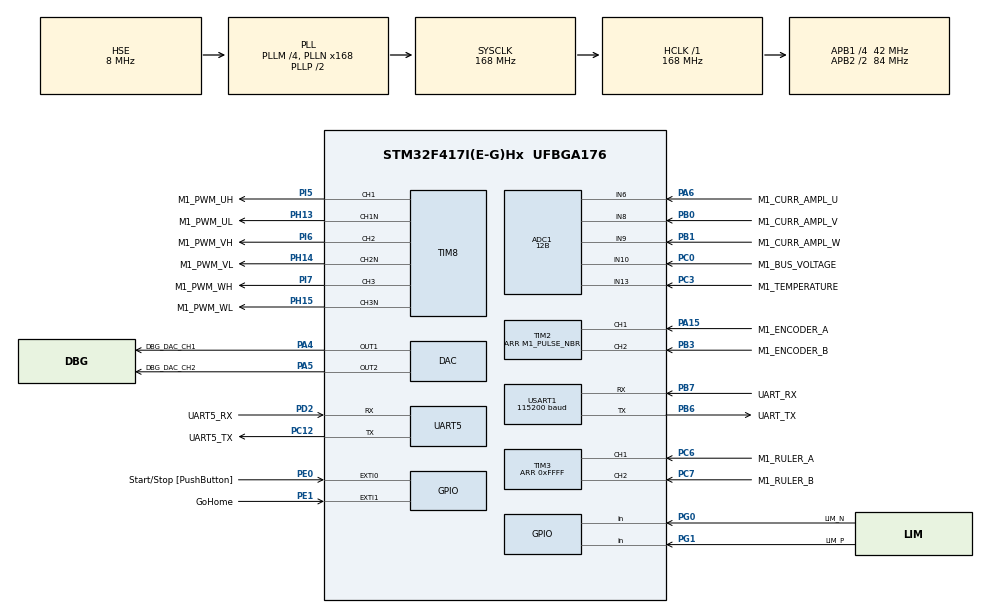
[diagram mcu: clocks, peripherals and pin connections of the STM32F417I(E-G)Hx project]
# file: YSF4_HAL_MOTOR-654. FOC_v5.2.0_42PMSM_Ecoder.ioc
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ADC1.Channel-1\#ChannelInjectedConversion=ADC_CHANNEL_6
ADC1.Channel-1\#ChannelRegularConversion=ADC_CHANNEL_10
ADC1.Channel-2\#ChannelInjectedConversion=ADC_CHANNEL_8
ADC1.Channel-2\#ChannelRegularConversion=ADC_CHANNEL_13
ADC1.Channel-3\#ChannelInjectedConversion=ADC_CHANNEL_9
ADC1.ClockPrescaler=ADC_CLOCK_SYNC_PCLK_DIV4
ADC1.ContinuousConvMode=DISABLE
ADC1.DMAContinuousRequests=DISABLE
ADC1.DataAlign=ADC_DATAALIGN_LEFT
ADC1.DiscontinuousConvMode=DISABLE
ADC1.EOCSelection=ADC_EOC_SINGLE_CONV
ADC1.EnableAnalogWatchDog=false
ADC1.EnableInjectedConversion=ENABLE
ADC1.EnableRegularConversion=ENABLE
ADC1.ExternalTrigConv=ADC_SOFTWARE_START
ADC1.ExternalTrigConvEdge=ADC_EXTERNALTRIGCONVEDGE_NONE
ADC1.ExternalTrigInjecConv=ADC_EXTERNALTRIGINJECCONV_T8_CC4
ADC1.ExternalTrigInjecConvEdge=ADC_EXTERNALTRIGINJECCONVEDGE_RISING
ADC1.InjNumberOfConversion=3
ADC1.InjectedConvMode=Discontinuous
ADC1.InjectedOffset-1\#ChannelInjectedConversion=0
ADC1.InjectedOffset-2\#ChannelInjectedConversion=0
ADC1.InjectedOffset-3\#ChannelInjectedConversion=0
ADC1.NbrOfConversion=2
ADC1.NbrOfConversionFlag=1
ADC1.Offset-1\#ChannelRegularConversion=0
ADC1.Offset-2\#ChannelRegularConversion=0
ADC1.OffsetNumber-1\#ChannelRegularConversion=ADC_OFFSET_NONE
ADC1.OffsetNumber-2\#ChannelRegularConversion=ADC_OFFSET_NONE
ADC1.Rank-1\#ChannelInjectedConversion=1
ADC1.Rank-1\#ChannelRegularConversion=1
ADC1.Rank-2\#ChannelInjectedConversion=2
ADC1.Rank-2\#ChannelRegularConversion=2
ADC1.Rank-3\#ChannelInjectedConversion=3
ADC1.Resolution=ADC_RESOLUTION_12B
ADC1.SamplingTime-1\#ChannelInjectedConversion=ADC_SAMPLETIME_3CYCLES
ADC1.SamplingTime-1\#ChannelRegularConversion=ADC_SAMPLETIME_56CYCLES
ADC1.SamplingTime-2\#ChannelInjectedConversion=ADC_SAMPLETIME_3CYCLES
ADC1.SamplingTime-2\#ChannelRegularConversion=ADC_SAMPLETIME_28CYCLES
ADC1.SamplingTime-3\#ChannelInjectedConversion=ADC_SAMPLETIME_3CYCLES
ADC1.ScanConvMode=ENABLE
ADC1.master=1
ADC2.Channel-1\#ChannelInjectedConversion=ADC_CHANNEL_6
ADC2.Channel-1\#ChannelRegularConversion=ADC_CHANNEL_6
ADC2.Channel-2\#ChannelInjectedConversion=ADC_CHANNEL_8
ADC2.Channel-3\#ChannelInjectedConversion=ADC_CHANNEL_9
ADC2.ClockPrescaler=ADC_CLOCK_SYNC_PCLK_DIV4
ADC2.ContinuousConvMode=DISABLE
ADC2.DMAContinuousRequests=DISABLE
ADC2.DataAlign=ADC_DATAALIGN_LEFT
ADC2.DiscontinuousConvMode=DISABLE
ADC2.EOCSelection=ADC_EOC_SINGLE_CONV
ADC2.EnableAnalogWatchDog=false
ADC2.EnableInjectedConversion=ENABLE
ADC2.EnableRegularConversion=ENABLE
ADC2.ExternalTrigConv=ADC_SOFTWARE_START
ADC2.ExternalTrigConvEdge=ADC_EXTERNALTRIGCONVEDGE_NONE
ADC2.ExternalTrigInjecConv=ADC_EXTERNALTRIGINJECCONV_T8_CC4
ADC2.ExternalTrigInjecConvEdge=ADC_EXTERNALTRIGINJECCONVEDGE_RISING
ADC2.InjNumberOfConversion=3
ADC2.InjectedConvMode=Discontinuous
ADC2.InjectedOffset-1\#ChannelInjectedConversion=0
ADC2.InjectedOffset-2\#ChannelInjectedConversion=0
ADC2.InjectedOffset-3\#ChannelInjectedConversion=0
ADC2.NbrOfConversion=1
ADC2.NbrOfConversionFlag=1
ADC2.Rank-1\#ChannelInjectedConversion=1
ADC2.Rank-1\#ChannelRegularConversion=1
ADC2.Rank-2\#ChannelInjectedConversion=2
ADC2.Rank-3\#ChannelInjectedConversion=3
ADC2.Resolution=ADC_RESOLUTION_12B
ADC2.SamplingTime-1\#ChannelInjectedConversion=ADC_SAMPLETIME_3CYCLES
ADC2.SamplingTime-1\#ChannelRegularConversion=ADC_SAMPLETIME_3CYCLES
ADC2.SamplingTime-2\#ChannelInjectedConversion=ADC_SAMPLETIME_3CYCLES
ADC2.SamplingTime-3\#ChannelInjectedConversion=ADC_SAMPLETIME_3CYCLES
ADC2.ScanConvMode=ENABLE
DAC.DAC_OutputBuffer=DAC_OUTPUTBUFFER_DISABLE
DAC.DAC_OutputBuffer2=DAC_OUTPUTBUFFER_DISABLE
DAC.DAC_Trigger=DAC_TRIGGER_SOFTWARE
DAC.DAC_Trigger2=DAC_TRIGGER_SOFTWARE
ExtraMW=MotorControl
ExtraMW.MotorControl.Config=MotorControl
ExtraMW.MotorControl.Mode=MotorControl
ExtraMW.MotorControl.Root=MCSDK_v5.2.0-Full/MotorControl
ExtraMW.MotorControl.Template=templates
Mcu.Family=STM32F4
Mcu.Name=STM32F417I(E-G)Hx
Mcu.Package=UFBGA176
MotorControl.ADC_1_PERIPH=ADC1
MotorControl.ADC_2_PERIPH=ADC2
MotorControl.ADC_AHBPERIPH=RCC_AHBPeriph_ADC12
MotorControl.ADC_CLOCK_WB_DIV=1
MotorControl.ADC_CLOCK_WB_FREQ=21
MotorControl.ADC_PERIPH=ADC1
MotorControl.ALIGNMENT_ANGLE_DEG=90
MotorControl.ALIGNMENT_DURATION=700
MotorControl.AMPLIFICATION_GAIN=4.02
MotorControl.ANGC={0,0,0,0,0,0,0,0}
MotorControl.BEMF_CONSISTENCY_GAIN=64
MotorControl.BEMF_CONSISTENCY_TOL=64
MotorControl.BKIN1_FILTER=0
MotorControl.BKIN2_FILTER=0
MotorControl.BKIN2_MODE=NONE
MotorControl.BKIN_MODE=NONE
MotorControl.BOARD=CUSTOM
MotorControl.BRKIN2_GPIO_AF=GPIO_AF_2
MotorControl.BRKIN_GPIO_AF=GPIO_AF_2
MotorControl.BUS_VOLTAGE_READING=true
MotorControl.CLOCK_FREQUENCY=CPU_CLK_168_MHZ
MotorControl.CLOCK_SOURCE=EXTERNAL
MotorControl.CONSTANT1_D=284329
MotorControl.CONSTANT1_Q=284329
MotorControl.CONSTANT2_QD=23067
MotorControl.CORD_BEMF_CONSISTENCY_GAIN=64
MotorControl.CORD_BEMF_CONSISTENCY_TOL=64
MotorControl.CORD_F1=16384
MotorControl.CORD_F2=2048
MotorControl.CORD_FIFO_DEPTH_01HZ=64
MotorControl.CORD_FIFO_DEPTH_DPP=64
MotorControl.CORD_GAIN1=-23771
MotorControl.CORD_GAIN2=23965
MotorControl.CORD_MAX_ACCEL_DPPP=60
MotorControl.CORD_MEAS_ERRORS_BEFORE_FAULTS=200
MotorControl.CORD_VARIANCE_THRESHOLD=4
MotorControl.CPU_CLK_168_MHZ=true
MotorControl.CTRBDID=4
MotorControl.CURRENT_READING_TOPOLOGY=THREE_SHUNT_INDEPENDENT_RESOURCES
MotorControl.CURR_SAMPLING_TIME=3
MotorControl.DAC_EMULATED=false
MotorControl.DAC_FUNCTIONALITY=true
MotorControl.DAC_TIMER_CH1_GPIO_PIN=LL_GPIO_PIN_4
MotorControl.DAC_TIMER_CH1_GPIO_PORT=GPIOA
MotorControl.DAC_TIMER_CH2_GPIO_PIN=LL_GPIO_PIN_5
MotorControl.DAC_TIMER_CH2_GPIO_PORT=GPIOA
MotorControl.DAC_TIMER_REMAPPING=NO_REMAP
MotorControl.DAC_TIMER_SELECTION=TIM3
MotorControl.DC_CURRENT_RS_MEAS=3.13
MotorControl.DEBUG_DAC_CH1=true
MotorControl.DEBUG_DAC_CH2=true
MotorControl.DEFAULT_CONTROL_MODE=STC_SPEED_MODE
MotorControl.DEFAULT_DAC_CHANNEL_1=MC_PROTOCOL_REG_I_A
MotorControl.DEFAULT_DAC_CHANNEL_2=MC_PROTOCOL_REG_I_B
MotorControl.DEFAULT_DAC_MOTOR=0
MotorControl.DEFAULT_FLUX_COMPONENT=0
MotorControl.DEFAULT_TARGET_SPEED_RPM=1000
MotorControl.DEFAULT_TORQUE_COMPONENT=0
MotorControl.DISSIPATIVE_BRAKE_POLARITY=DOUT_ACTIVE_HIGH
MotorControl.DRIVES_NUMBER_SELECTION=SINGLEDRIVE
MotorControl.EMERGENCY2_STOP_GPIO_PIN=LL_GPIO_PIN_4
MotorControl.EMERGENCY2_STOP_GPIO_PORT=GPIOI
MotorControl.EMERGENCY_STOP_GPIO_PIN=LL_GPIO_PIN_4
MotorControl.EMERGENCY_STOP_GPIO_PORT=GPIOI
MotorControl.ENABLE_SL_ALGO_FROM_PHASE=3
MotorControl.ENCODER=true
MotorControl.ENCODER_AVAILABLE=true
MotorControl.ENCODER_PPR=1000
MotorControl.ENC_AVERAGING_FIFO_DEPTH=16
MotorControl.ENC_A_GPIO_PIN=LL_GPIO_PIN_15
MotorControl.ENC_A_GPIO_PORT=GPIOA
MotorControl.ENC_B_GPIO_PIN=LL_GPIO_PIN_3
MotorControl.ENC_B_GPIO_PORT=GPIOB
MotorControl.ENC_ICx_FILTER=17
MotorControl.ENC_INVERT_SPEED=false
MotorControl.ENC_MEAS_ERRORS_BEFORE_FAULTS=200
MotorControl.ENC_TIMER_REMAPPING=NO_REMAP_TIM2
MotorControl.ENC_TIMER_SELECTION=ENC_TIM2
MotorControl.EXT_CLK_8_MHZ=true
MotorControl.EXT_CLOCK_FREQUENCY=EXT_CLK_8_MHZ
MotorControl.F1=16384
MotorControl.F2=2048
MotorControl.FEEDBACK_NET_FILTERING=false
MotorControl.FEED_FORWARD_CURRENT_REG_ENABLING=false
MotorControl.FINAL_I_ALIGNMENT=1596
MotorControl.FLUX_WEAKENING_ENABLING=false
MotorControl.FW_KIDIV=32768
MotorControl.FW_KI_GAIN=5000
MotorControl.FW_KPDIV=32768
MotorControl.FW_KP_GAIN=3000
MotorControl.FW_VOLTAGE_REF=985
MotorControl.GAIN1=-23771
MotorControl.GAIN2=23965
MotorControl.H1_GPIO_PIN=LL_GPIO_PIN_10
MotorControl.H1_GPIO_PORT=GPIOH
MotorControl.H2_GPIO_PIN=LL_GPIO_PIN_11
MotorControl.H2_GPIO_PORT=GPIOH
MotorControl.H3_GPIO_PIN=LL_GPIO_PIN_12
MotorControl.H3_GPIO_PORT=GPIOH
MotorControl.HALL_AVERAGING_FIFO_DEPTH=6
MotorControl.HALL_ICx_FILTER=218
MotorControl.HALL_MEAS_ERRORS_BEFORE_FAULTS=200
MotorControl.HALL_PHASE_SHIFT=120
MotorControl.HALL_SENSORS_AVAILABLE=true
MotorControl.HALL_SENSORS_PLACEMENT=DEGREES_120
MotorControl.HALL_TIMER_REMAPPING=NO_REMAP_TIM5
MotorControl.HALL_TIMER_SELECTION=HALL_TIM5
MotorControl.HFI_AMPLITUDE=25
MotorControl.HFI_DC_0_COEFF=0.00146
MotorControl.HFI_DC_1_COEFF=0.002921
MotorControl.HFI_DC_2_COEFF=0.00146
MotorControl.HFI_DC_3_COEFF=1.889033
MotorControl.HFI_DC_4_COEFF=-0.894874
MotorControl.HFI_DEBUG_MODE=false
MotorControl.HFI_FREQUENCY=400
MotorControl.HFI_HIFRAMPLSCAN=25
MotorControl.HFI_HP_ID_0_COEFF=0.925191
MotorControl.HFI_HP_ID_1_COEFF=-1.850383
MotorControl.HFI_HP_ID_2_COEFF=0.925191
MotorControl.HFI_HP_ID_3_COEFF=1.844778
MotorControl.HFI_HP_ID_4_COEFF=-0.855987
MotorControl.HFI_IDH_DELAY=32400
MotorControl.HFI_LOCKFREQ=41
MotorControl.HFI_LP_ID_0_COEFF=0.009086
MotorControl.HFI_LP_ID_1_COEFF=0.018172
MotorControl.HFI_LP_ID_2_COEFF=0.009086
MotorControl.HFI_LP_ID_3_COEFF=1.712838
MotorControl.HFI_LP_ID_4_COEFF=-0.749181
MotorControl.HFI_MAXANGLEDIFF=3640
MotorControl.HFI_MINIMUM_SPEED_RPM=402
MotorControl.HFI_NOTCH_IQD_0_COEFF=0.962363
MotorControl.HFI_NOTCH_IQD_1_COEFF=-1.90103
MotorControl.HFI_NOTCH_IQD_2_COEFF=0.962363
MotorControl.HFI_NOTCH_IQD_3_COEFF=1.90103
MotorControl.HFI_NOTCH_IQD_4_COEFF=-0.924727
MotorControl.HFI_NSDETPOINTSSKIP=10
MotorControl.HFI_NSMAXDETPOINTS=20
MotorControl.HFI_NS_MIN_SAT_DIFF=0
MotorControl.HFI_PID_KIDIV=32768
MotorControl.HFI_PID_KI_DEFAULT=400
MotorControl.HFI_PID_KPDIV=16384
MotorControl.HFI_PID_KP_DEFAULT=800
MotorControl.HFI_PLL_KI_DEFAULT=0.00400
MotorControl.HFI_PLL_KP_DEFAULT=0.00060
MotorControl.HFI_RESTARTTIMESEC=0.1
MotorControl.HFI_RESTART_RPM_TH=(((HFI_STO_RPM_TH)+(STO_HFI_RPM_TH))/2)
MotorControl.HFI_REVERT_DIRECTION=true
MotorControl.HFI_SCANROTATIONSNO=3
MotorControl.HFI_SPD_BUFFER_DEPTH_01HZ=64
MotorControl.HFI_STEPANGLE=3640
MotorControl.HFI_STO_RPM_TH=OBS_MINIMUM_SPEED_RPM
MotorControl.HFI_WAITAFTERNS2=4
MotorControl.HFI_WAITBEFORESN=6
MotorControl.HFI_WAITSYNCH=20
MotorControl.HFI_WAITTRACK=20
MotorControl.HIGH_SIDE_BRAKE_STATE=false
MotorControl.HIGH_SIDE_IDLE_STATE=false
MotorControl.HW_COMPLEMENTED_LOW_SIDE=false
MotorControl.HW_DEAD_TIME_NS=100
MotorControl.HW_OV_CURRENT_PROT_BYPASS=false
MotorControl.ID_DEMAG=-4997
MotorControl.INRUSH_CURRLIMIT_AT_POWER_ON=true
MotorControl.INRUSH_CURRLIMIT_CHANGE_AFTER_MS=1000
MotorControl.INRUSH_CURRLIMIT_ENABLING=false
MotorControl.INRUSH_CURRLIMIT_GPIO_PIN=LL_GPIO_PIN_8
MotorControl.INRUSH_CURRLIMIT_GPIO_PORT=GPIOH
MotorControl.INRUSH_CURR_LIMITER_POLARITY=DOUT_ACTIVE_HIGH
MotorControl.INTERNAL_OVERCURRENTPROTECTION=false
MotorControl.INTERNAL_OVERVOLTAGEPROTECTION=false
MotorControl.IQMAX=4997
MotorControl.LCD_JOYSTICK_FUNCTIONALITY=false
MotorControl.LCD_MODE=LCD_FULL
MotorControl.LDLQ_RATIO=1.000
MotorControl.LOW_SIDE_BRAKE_STATE=false
MotorControl.LOW_SIDE_IDLE_STATE=false
MotorControl.LOW_SIDE_SIGNALS_ENABLING=LS_PWM_TIMER
MotorControl.LS=0.000620
MotorControl.MAX_APPLICATION_SPEED=3000
MotorControl.MAX_MODULATION_99_PER_CENT=true
MotorControl.MAX_MODULATION_INDEX=MAX_MODULATION_99_PER_CENT
MotorControl.MCU=STM32F417IG
MotorControl.MCU_SUPPLY_VOLTAGE=3.30
MotorControl.MCU_TYPE=STM32F4xx
MotorControl.MC_WORKBENCH_VERSION=5.2.0.18503
MotorControl.MEAS_ERRORS_BEFORE_FAULTS=200
MotorControl.MIN_APPLICATION_SPEED=0
MotorControl.MOTOR_MAX_SPEED_RPM=3000
MotorControl.MOTOR_TYPE=PMSM
MotorControl.MOTOR_VOLTAGE_CONSTANT=4.1
MotorControl.MTPA_ENABLING=false
MotorControl.NB_CONSECUTIVE_TESTS=2
MotorControl.NOMINAL_BUS_VOLTAGE_V=24
MotorControl.NOMINAL_CURRENT=4997
MotorControl.OBS_MEAS_ERRORS_BEFORE_FAULTS=200
MotorControl.OBS_MINIMUM_SPEED_RPM=580
MotorControl.OCPA_INVERTINGINPUT=COMPX_InvertingInput_VREF
MotorControl.OCPA_INVERTINGINPUT_GPIO_PIN=LL_GPIO_PIN_4
MotorControl.OCPA_INVERTINGINPUT_GPIO_PORT=GPIOA
MotorControl.OCPA_INVERTINGINPUT_MODE=INT_MODE
MotorControl.OCPA_NONINVERTINGINPUT=COMP1_NonInvertingInput_PA1
MotorControl.OCPA_NONINVERTINGINPUT_GPIO_PIN=LL_GPIO_PIN_1
MotorControl.OCPA_NONINVERTINGINPUT_GPIO_PORT=GPIOA
MotorControl.OCPA_OUTPUT=COMP_Output_TIM8BKIN2
MotorControl.OCPA_OUTPUTPOL=COMP_OutputPol_NonInverted
MotorControl.OCPA_OUTPUT_GPIO_AF=GPIO_AF_8
MotorControl.OCPA_OUTPUT_GPIO_PIN=LL_GPIO_PIN_0
MotorControl.OCPA_OUTPUT_GPIO_PORT=GPIOA
MotorControl.OCPA_OUTPUT_MODE=INT_MODE
MotorControl.OCPA_SELECTION=COMP1
MotorControl.OCPB_INVERTINGINPUT=COMPX_InvertingInput_VREF
MotorControl.OCPB_INVERTINGINPUT_GPIO_PIN=LL_GPIO_PIN_4
MotorControl.OCPB_INVERTINGINPUT_GPIO_PORT=GPIOA
MotorControl.OCPB_INVERTINGINPUT_MODE=INT_MODE
MotorControl.OCPB_NONINVERTINGINPUT=COMP2_NonInvertingInput_PA7
MotorControl.OCPB_NONINVERTINGINPUT_GPIO_PIN=LL_GPIO_PIN_7
MotorControl.OCPB_NONINVERTINGINPUT_GPIO_PORT=GPIOA
MotorControl.OCPB_OUTPUT=COMP_Output_TIM8BKIN2
MotorControl.OCPB_OUTPUTPOL=COMP_OutputPol_NonInverted
MotorControl.OCPB_OUTPUT_GPIO_AF=GPIO_AF_8
MotorControl.OCPB_OUTPUT_GPIO_PIN=LL_GPIO_PIN_2
MotorControl.OCPB_OUTPUT_GPIO_PORT=GPIOA
MotorControl.OCPB_OUTPUT_MODE=INT_MODE
MotorControl.OCPB_SELECTION=COMP2
MotorControl.OCPC_INVERTINGINPUT=COMPX_InvertingInput_VREF
MotorControl.OCPC_INVERTINGINPUT_GPIO_PIN=LL_GPIO_PIN_4
MotorControl.OCPC_INVERTINGINPUT_GPIO_PORT=GPIOA
MotorControl.OCPC_INVERTINGINPUT_MODE=INT_MODE
MotorControl.OCPC_NONINVERTINGINPUT=COMP3_NonInvertingInput_PD14
MotorControl.OCPC_NONINVERTINGINPUT_GPIO_PIN=LL_GPIO_PIN_14
MotorControl.OCPC_NONINVERTINGINPUT_GPIO_PORT=GPIOD
MotorControl.OCPC_OUTPUT=COMP_Output_TIM8BKIN2
MotorControl.OCPC_OUTPUTPOL=COMP_OutputPol_NonInverted
MotorControl.OCPC_OUTPUT_GPIO_AF=GPIO_AF_7
MotorControl.OCPC_OUTPUT_GPIO_PIN=LL_GPIO_PIN_8
MotorControl.OCPC_OUTPUT_GPIO_PORT=GPIOC
MotorControl.OCPC_OUTPUT_MODE=INT_MODE
MotorControl.OCPC_SELECTION=COMP3
MotorControl.OCPREF=23830
MotorControl.OCP_COMP_THRESHOLD=0.50
MotorControl.OCP_FILTER=COMP_Mode_HighSpeed
MotorControl.OCP_INVERTINGINPUT=COMPX_InvertingInput_VREF
MotorControl.OCP_INVERTINGINPUT_GPIO_PIN=LL_GPIO_PIN_4
MotorControl.OCP_INVERTINGINPUT_GPIO_PORT=GPIOA
MotorControl.OCP_INVERTINGINPUT_MODE=INT_MODE
MotorControl.OCP_NONINVERTINGINPUT=COMP2_NonInvertingInput_PA7
MotorControl.OCP_NONINVERTINGINPUT_GPIO_PIN=LL_GPIO_PIN_7
MotorControl.OCP_NONINVERTINGINPUT_GPIO_PORT=GPIOA
MotorControl.OCP_OUTPUT=COMP_Output_TIM8BKIN2
MotorControl.OCP_OUTPUTPOL=COMP_OutputPol_NonInverted
MotorControl.OCP_OUTPUT_GPIO_AF=GPIO_AF_8
MotorControl.OCP_OUTPUT_GPIO_PIN=LL_GPIO_PIN_2
MotorControl.OCP_OUTPUT_GPIO_PORT=GPIOA
MotorControl.OCP_OUTPUT_MODE=INT_MODE
MotorControl.OCP_SELECTION=COMP2
MotorControl.OFST={0,0,0,0,0,0,0,0}
MotorControl.ON_OVER_VOLTAGE=TURN_OFF_PWM
MotorControl.OPAMP1_INVERTINGINPUT=OPAMP1_InvertingInput_PGA
MotorControl.OPAMP1_INVERTINGINPUT_GPIO_PIN=LL_GPIO_PIN_3
MotorControl.OPAMP1_INVERTINGINPUT_GPIO_PORT=GPIOA
MotorControl.OPAMP1_INVERTINGINPUT_MODE=INT_MODE
MotorControl.OPAMP1_NONINVERTINGINPUT_PHA=OPAMP1_NonInvertingInput_PA1
MotorControl.OPAMP1_NONINVERTINGINPUT_PHA_GPIO_PIN=LL_GPIO_PIN_1
MotorControl.OPAMP1_NONINVERTINGINPUT_PHA_GPIO_PORT=GPIOA
MotorControl.OPAMP1_NONINVERTINGINPUT_PHB=OPAMP1_NonInvertingInput_PA7
MotorControl.OPAMP1_NONINVERTINGINPUT_PHB_GPIO_PIN=LL_GPIO_PIN_7
MotorControl.OPAMP1_NONINVERTINGINPUT_PHB_GPIO_PORT=GPIOA
MotorControl.OPAMP1_OUT_GPIO_PIN=LL_GPIO_PIN_2
MotorControl.OPAMP1_OUT_GPIO_PORT=GPIOA
MotorControl.OPAMP1_SELECTION=OPAMP1
MotorControl.OPAMP2_INVERTINGINPUT=OPAMP2_InvertingInput_PGA
MotorControl.OPAMP2_INVERTINGINPUT_GPIO_PIN=LL_GPIO_PIN_5
MotorControl.OPAMP2_INVERTINGINPUT_GPIO_PORT=GPIOC
MotorControl.OPAMP2_INVERTINGINPUT_MODE=INT_MODE
MotorControl.OPAMP2_NONINVERTINGINPUT_PHA=OPAMP2_NonInvertingInput_PD14
MotorControl.OPAMP2_NONINVERTINGINPUT_PHA_GPIO_PIN=LL_GPIO_PIN_14
MotorControl.OPAMP2_NONINVERTINGINPUT_PHA_GPIO_PORT=GPIOD
MotorControl.OPAMP2_NONINVERTINGINPUT_PHB=OPAMP2_NonInvertingInput_PA7
MotorControl.OPAMP2_NONINVERTINGINPUT_PHB_GPIO_PIN=LL_GPIO_PIN_7
MotorControl.OPAMP2_NONINVERTINGINPUT_PHB_GPIO_PORT=GPIOA
MotorControl.OPAMP2_NONINVERTINGINPUT_PHC=OPAMP2_NonInvertingInput_PD14
MotorControl.OPAMP2_NONINVERTINGINPUT_PHC_GPIO_PIN=LL_GPIO_PIN_14
MotorControl.OPAMP2_NONINVERTINGINPUT_PHC_GPIO_PORT=GPIOD
MotorControl.OPAMP2_OUT_GPIO_PIN=LL_GPIO_PIN_6
MotorControl.OPAMP2_OUT_GPIO_PORT=GPIOA
MotorControl.OPAMP2_SELECTION=OPAMP2
MotorControl.OPAMP_INVERTINGINPUT=OPAMP1_InvertingInput_PGA
MotorControl.OPAMP_INVERTINGINPUT_GPIO_PIN=LL_GPIO_PIN_3
MotorControl.OPAMP_INVERTINGINPUT_GPIO_PORT=GPIOA
MotorControl.OPAMP_INVERTINGINPUT_MODE=INT_MODE
MotorControl.OPAMP_NONINVERTINGINPUT=OPAMP1_NonInvertingInput_PA7
MotorControl.OPAMP_NONINVERTINGINPUT_GPIO_PIN=LL_GPIO_PIN_7
MotorControl.OPAMP_NONINVERTINGINPUT_GPIO_PORT=GPIOA
MotorControl.OPAMP_OUT_GPIO_PIN=LL_GPIO_PIN_2
MotorControl.OPAMP_OUT_GPIO_PORT=GPIOA
MotorControl.OPAMP_PGACONNECT=OPAMP_PGAConnect_No
MotorControl.OPAMP_PGAGAIN=OPAMP_OPAMP_PGAGain_2
MotorControl.OPAMP_SELECTION=OPAMP1
MotorControl.OPAMP_TYPE_GAIN=INTERNAL
MotorControl.OPEN_LOOP_FOC=false
MotorControl.OPEN_LOOP_K=44
MotorControl.OPEN_LOOP_OFF=4400
MotorControl.OPEN_LOOP_SPEED_RAMP_DURATION_MS=1000
MotorControl.OPEN_LOOP_SPEED_RPM=100
MotorControl.OPEN_LOOP_VF=false
MotorControl.OPEN_LOOP_VOLTAGE_d=6000
MotorControl.OVERCURR_FEEDBACK_POLARITY=EMSTOP_ACTIVE_LOW
MotorControl.OVERCURR_PROTECTION_HW_DISABLING=DOUT_ACTIVE_HIGH
MotorControl.OVPREF=23830
MotorControl.OVP_FILTER=COMP_Mode_HighSpeed
MotorControl.OVP_INVERTINGINPUT=COMPX_InvertingInput_VREF
MotorControl.OVP_INVERTINGINPUT_GPIO_PIN=LL_GPIO_PIN_4
MotorControl.OVP_INVERTINGINPUT_GPIO_PORT=GPIOA
MotorControl.OVP_INVERTINGINPUT_MODE=INT_MODE
MotorControl.OVP_NONINVERTINGINPUT=COMP7_NonInvertingInput_PA0
MotorControl.OVP_NONINVERTINGINPUT_GPIO_PIN=LL_GPIO_PIN_0
MotorControl.OVP_NONINVERTINGINPUT_GPIO_PORT=GPIOA
MotorControl.OVP_OUTPUT=COMP_Output_TIM8BKIN
MotorControl.OVP_OUTPUTPOL=COMP_OutputPol_NonInverted
MotorControl.OVP_OUTPUT_GPIO_AF=GPIO_AF_3
MotorControl.OVP_OUTPUT_GPIO_PIN=LL_GPIO_PIN_2
MotorControl.OVP_OUTPUT_GPIO_PORT=GPIOC
MotorControl.OVP_OUTPUT_MODE=INT_MODE
MotorControl.OVP_SELECTION=COMP7
MotorControl.OV_CURR_BYPASS_GPIO_PIN=LL_GPIO_PIN_8
MotorControl.OV_CURR_BYPASS_GPIO_PORT=GPIOC
MotorControl.OV_TEMPERATURE_HYSTERESIS_C=10
MotorControl.OV_TEMPERATURE_PROT_ENABLING=true
MotorControl.OV_TEMPERATURE_THRESHOLD_C=70
MotorControl.OV_VOLTAGE_PROT_ENABLING=true
MotorControl.OV_VOLTAGE_THRESHOLD_V=60
MotorControl.PHASE1_DURATION=0
MotorControl.PHASE1_FINAL_CURRENT=0
MotorControl.PHASE1_FINAL_SPEED_RPM=0
MotorControl.PHASE2_DURATION=700
MotorControl.PHASE2_FINAL_CURRENT=957
MotorControl.PHASE2_FINAL_SPEED_RPM=0
MotorControl.PHASE3_DURATION=350
MotorControl.PHASE3_FINAL_CURRENT=1117
MotorControl.PHASE3_FINAL_SPEED_RPM=630
MotorControl.PHASE4_DURATION=1150
MotorControl.PHASE4_FINAL_CURRENT=1117
MotorControl.PHASE4_FINAL_SPEED_RPM=2700
MotorControl.PHASE5_DURATION=0
MotorControl.PHASE5_FINAL_CURRENT=1117
MotorControl.PHASE5_FINAL_SPEED_RPM=2700
MotorControl.PHASE_CURRENTS_ADC=ADC123
MotorControl.PHASE_CURRENTS_CHANNEL=ADC_CHANNEL_11
MotorControl.PHASE_CURRENTS_GPIO_PIN=LL_GPIO_PIN_1
MotorControl.PHASE_CURRENTS_GPIO_PORT=GPIOC
MotorControl.PHASE_UH_GPIO_AF=GPIO_AF_2
MotorControl.PHASE_UH_GPIO_PIN=LL_GPIO_PIN_5
MotorControl.PHASE_UH_GPIO_PORT=GPIOI
MotorControl.PHASE_UH_POLARITY=H_ACTIVE_HIGH
MotorControl.PHASE_UL_GPIO_AF=GPIO_AF_2
MotorControl.PHASE_UL_GPIO_PIN=LL_GPIO_PIN_13
MotorControl.PHASE_UL_GPIO_PORT=GPIOH
MotorControl.PHASE_UL_POLARITY=L_ACTIVE_HIGH
MotorControl.PHASE_U_CURR_ADC=ADC1_2
MotorControl.PHASE_U_CURR_CHANNEL=ADC_CHANNEL_6
MotorControl.PHASE_U_GPIO_PIN=LL_GPIO_PIN_6
MotorControl.PHASE_U_GPIO_PORT=GPIOA
MotorControl.PHASE_VH_GPIO_AF=GPIO_AF_2
MotorControl.PHASE_VH_GPIO_PIN=LL_GPIO_PIN_6
MotorControl.PHASE_VH_GPIO_PORT=GPIOI
MotorControl.PHASE_VH_POLARITY=H_ACTIVE_HIGH
MotorControl.PHASE_VL_GPIO_AF=GPIO_AF_2
MotorControl.PHASE_VL_GPIO_PIN=LL_GPIO_PIN_14
MotorControl.PHASE_VL_GPIO_PORT=GPIOH
MotorControl.PHASE_VL_POLARITY=L_ACTIVE_HIGH
MotorControl.PHASE_V_CURR_ADC=ADC1_2
MotorControl.PHASE_V_CURR_CHANNEL=ADC_CHANNEL_8
MotorControl.PHASE_V_GPIO_PIN=LL_GPIO_PIN_0
MotorControl.PHASE_V_GPIO_PORT=GPIOB
MotorControl.PHASE_WH_GPIO_AF=GPIO_AF_2
MotorControl.PHASE_WH_GPIO_PIN=LL_GPIO_PIN_7
MotorControl.PHASE_WH_GPIO_PORT=GPIOI
MotorControl.PHASE_WH_POLARITY=H_ACTIVE_HIGH
MotorControl.PHASE_WL_GPIO_AF=GPIO_AF_2
MotorControl.PHASE_WL_GPIO_PIN=LL_GPIO_PIN_15
MotorControl.PHASE_WL_GPIO_PORT=GPIOH
MotorControl.PHASE_WL_POLARITY=L_ACTIVE_HIGH
MotorControl.PHASE_W_CURR_ADC=ADC1_2
MotorControl.PHASE_W_CURR_CHANNEL=ADC_CHANNEL_9
MotorControl.PHASE_W_GPIO_PIN=LL_GPIO_PIN_1
MotorControl.PHASE_W_GPIO_PORT=GPIOB
MotorControl.PID_FLUX_KD_DEFAULT=100
MotorControl.PID_FLUX_KI_DEFAULT=2277
MotorControl.PID_FLUX_KP_DEFAULT=2172
MotorControl.PID_SPEED_KD_DEFAULT=0
MotorControl.PID_SPEED_KI_DEFAULT=50
MotorControl.PID_SPEED_KP_DEFAULT=100
MotorControl.PID_TORQUE_KD_DEFAULT=100
MotorControl.PID_TORQUE_KI_DEFAULT=2277
MotorControl.PID_TORQUE_KP_DEFAULT=2172
MotorControl.PLL_KI_GAIN=17
MotorControl.PLL_KP_GAIN=399
MotorControl.POLE_PAIR_NUM=4
MotorControl.PWBDID=0
MotorControl.PWM_FREQUENCY=16000
MotorControl.PWM_TIMER_REMAPPING=PWM_NO_REMAP
MotorControl.PWM_TIMER_SELECTION=PWM_TIM8
MotorControl.REGCONVADC=ADC1
MotorControl.REGULATION_EXECUTION_RATE=1
MotorControl.RS=0.65
MotorControl.RSHUNT=0.020
MotorControl.R_BRAKE_GPIO_PIN=LL_GPIO_PIN_8
MotorControl.R_BRAKE_GPIO_PORT=GPIOC
MotorControl.R_BRAKE_SWITCH_OFF_THRES_V=48
MotorControl.SEGDIV=0
MotorControl.SERIAL_COMMUNICATION=true
MotorControl.SERIAL_COM_CHANNEL1=MC_PROTOCOL_REG_I_A
MotorControl.SERIAL_COM_CHANNEL2=MC_PROTOCOL_REG_I_A
MotorControl.SERIAL_COM_MODE=COM_BIDIRECTIONAL
MotorControl.SERIAL_COM_MOTOR=0
MotorControl.SHARED_SIGNAL_ENABLE=false
MotorControl.SINGLEDRIVE=true
MotorControl.SPD_DIFFERENTIAL_TERM_ENABLING=false
MotorControl.SPEED_BAND_LOWER_LIMIT=15
MotorControl.SPEED_BAND_UPPER_LIMIT=17
MotorControl.SPEED_LOOP_FREQUENCY_HZ=500
MotorControl.SPEED_SENSOR_SELECTION=ENCODER
MotorControl.SP_KDDIV=16
MotorControl.SP_KIDIV=256
MotorControl.SP_KPDIV=16
MotorControl.STARTING_ANGLE_DEG=90
MotorControl.START_STOP_BTN=true
MotorControl.START_STOP_GPIO_PIN=LL_GPIO_PIN_0
MotorControl.START_STOP_GPIO_PORT=GPIOE
MotorControl.START_STOP_POLARITY=DIN_ACTIVE_LOW
MotorControl.STM32F4xx=true
MotorControl.STO_FIFO_DEPTH_01HZ=64
MotorControl.STO_FIFO_DEPTH_DPP=64
MotorControl.STO_HFI_RPM_TH=460
MotorControl.SW_DEADTIME_NS=200
MotorControl.SW_OV_CURRENT_PROT_ENABLING=false
MotorControl.T0_C=25
MotorControl.TEMPERATURE_READING=true
MotorControl.TEMP_ADC_SAMPLING_TIME=28
MotorControl.TEMP_FDBK_ADC=ADC123
MotorControl.TEMP_FDBK_CHANNEL=ADC_CHANNEL_13
MotorControl.TEMP_FDBK_GPIO_PIN=LL_GPIO_PIN_3
MotorControl.TEMP_FDBK_GPIO_PORT=GPIOC
MotorControl.TFDIFFERENTIAL_TERM_ENABLING=false
MotorControl.TF_KDDIV=8192
MotorControl.TF_KIDIV=16384
MotorControl.TF_KPDIV=1024
MotorControl.THREE_SHUNT_INDEPENDENT_RESOURCES=true
MotorControl.TNOISE_NS=2550
MotorControl.TRANSITION_DURATION=25
MotorControl.TRISE_NS=2550
MotorControl.T_MAX=70
MotorControl.UD_VOLTAGE_THRESHOLD_V=12
MotorControl.USART_REMAPPING=NO_REMAP_USART1
MotorControl.USART_RX_GPIO_PIN=LL_GPIO_PIN_7
MotorControl.USART_RX_GPIO_PORT=GPIOB
MotorControl.USART_SELECTION=USE_USART1
MotorControl.USART_SPEED=115200
MotorControl.USART_TX_GPIO_PIN=LL_GPIO_PIN_6
MotorControl.USART_TX_GPIO_PORT=GPIOB
MotorControl.USE_INTERNAL_OPAMP=false
MotorControl.UV_VOLTAGE_PROT_ENABLING=true
MotorControl.V0_V=0.926
MotorControl.VARIANCE_THRESHOLD=0.1
MotorControl.VBUS_ADC=ADC123
MotorControl.VBUS_ADC_SAMPLING_TIME=56
MotorControl.VBUS_CHANNEL=ADC_CHANNEL_10
MotorControl.VBUS_GPIO_PIN=LL_GPIO_PIN_0
MotorControl.VBUS_GPIO_PORT=GPIOC
MotorControl.VBUS_PARTITIONING_FACTOR=0.0463
MotorControl.WB_to_Mx_template_version=18-08-02
MotorControl.WB_to_Mx_version=0.13.3
MotorControl.dV_dT=0.030
NVIC.ADC_IRQn=true\:2\:0\:true\:true\:false\:1\:false\:true\:true
NVIC.EXTI0_IRQn=true\:0\:0\:false\:true\:false\:6\:true\:true\:true
NVIC.EXTI1_IRQn=true\:0\:0\:false\:false\:true\:true\:true\:true
NVIC.PriorityGroup=NVIC_PRIORITYGROUP_3
NVIC.TIM2_IRQn=true\:3\:0\:false\:true\:false\:4\:true\:true\:true
NVIC.TIM3_IRQn=true\:0\:0\:false\:false\:true\:true\:true\:true
NVIC.TIM8_BRK_TIM12_IRQn=true\:4\:1\:false\:true\:false\:3\:true\:true\:true
NVIC.TIM8_UP_TIM13_IRQn=true\:0\:0\:false\:true\:false\:2\:true\:true\:true
NVIC.UART5_IRQn=true\:0\:0\:false\:false\:true\:true\:true\:true
NVIC.USART1_IRQn=true\:3\:1\:true\:true\:false\:5\:true\:true\:true
PA15.GPIO_Label=M1_ENCODER_A
PA15.Signal=S_TIM2_CH1_ETR
PA4.GPIO_Label=DBG_DAC_CH1
PA4.Signal=COMP_DAC1_group
PA5.GPIO_Label=DBG_DAC_CH2
PA5.Signal=COMP_DAC2_group
PA6.GPIO_Label=M1_CURR_AMPL_U
PA6.Signal=SharedAnalog_PA6
PB0.GPIO_Label=M1_CURR_AMPL_V
PB0.Signal=SharedAnalog_PB0
PB1.GPIO_Label=M1_CURR_AMPL_W
PB1.Signal=SharedAnalog_PB1
PB3.GPIO_Label=M1_ENCODER_B
PB3.Signal=S_TIM2_CH2
PB6.GPIO_Label=UART_TX
PB6.GPIO_Mode=GPIO_MODE_AF_PP
PB6.GPIO_PuPd=GPIO_NOPULL
PB6.GPIO_Speed=GPIO_SPEED_FREQ_LOW
PB6.Mode=Asynchronous
PB6.Signal=USART1_TX
PB7.GPIO_Label=UART_RX
PB7.GPIO_Mode=GPIO_MODE_AF_PP
PB7.GPIO_PuPd=GPIO_NOPULL
PB7.GPIO_Speed=GPIO_SPEED_FREQ_LOW
PB7.Mode=Asynchronous
PB7.Signal=USART1_RX
PC0.GPIO_Label=M1_BUS_VOLTAGE
PC0.Signal=ADCx_IN10
PC12.GPIO_Label=UART5_TX
PC12.GPIO_Speed=GPIO_SPEED_FREQ_LOW
PC12.Mode=Asynchronous
PC12.Signal=UART5_TX
PC3.GPIO_Label=M1_TEMPERATURE
PC3.Signal=ADCx_IN13
PC6.GPIO_Label=M1_RULER_A
PC6.Signal=S_TIM3_CH1
PC7.GPIO_Label=M1_RULER_B
PC7.Signal=S_TIM3_CH2
PD2.GPIO_Label=UART5_RX
PD2.GPIO_Speed=GPIO_SPEED_FREQ_LOW
PD2.Mode=Asynchronous
PD2.Signal=UART5_RX
PE0.GPIO_Label=Start/Stop [PushButton]
PE0.GPIO_ModeDefaultEXTI=GPIO_MODE_IT_FALLING
PE0.Signal=GPXTI0
PE1.GPIO_Label=GoHome
PE1.Signal=GPXTI1
PG0.GPIO_Label=LIM_N
PG0.Signal=GPIO_Input
PG1.GPIO_Label=LIM_P
PG1.Signal=GPIO_Input
PH0-OSC_IN.Mode=HSE-External-Oscillator
PH0-OSC_IN.Signal=RCC_OSC_IN
PH1-OSC_OUT.Mode=HSE-External-Oscillator
PH1-OSC_OUT.Signal=RCC_OSC_OUT
PH13.GPIO_Label=M1_PWM_UL
PH13.GPIO_PuPd=GPIO_PULLDOWN
PH13.GPIO_Speed=GPIO_SPEED_FREQ_HIGH
PH13.Mode=PWM Generation1 CH1 CH1N
PH13.Signal=TIM8_CH1N
PH14.GPIO_Label=M1_PWM_VL
PH14.GPIO_PuPd=GPIO_PULLDOWN
PH14.GPIO_Speed=GPIO_SPEED_FREQ_HIGH
PH14.Mode=PWM Generation2 CH2 CH2N
PH14.Signal=TIM8_CH2N
PH15.GPIO_Label=M1_PWM_WL
PH15.GPIO_PuPd=GPIO_PULLDOWN
PH15.GPIO_Speed=GPIO_SPEED_FREQ_HIGH
PH15.Mode=PWM Generation3 CH3 CH3N
PH15.Signal=TIM8_CH3N
PI5.GPIO_Label=M1_PWM_UH
PI5.GPIO_PuPd=GPIO_PULLDOWN
PI5.GPIO_Speed=GPIO_SPEED_FREQ_HIGH
PI5.Signal=S_TIM8_CH1
PI6.GPIO_Label=M1_PWM_VH
PI6.GPIO_PuPd=GPIO_PULLDOWN
PI6.GPIO_Speed=GPIO_SPEED_FREQ_HIGH
PI6.Signal=S_TIM8_CH2
PI7.GPIO_Label=M1_PWM_WH
PI7.GPIO_PuPd=GPIO_PULLDOWN
PI7.GPIO_Speed=GPIO_SPEED_FREQ_HIGH
PI7.Signal=S_TIM8_CH3
ProjectManager.HeapSize=0x200
ProjectManager.StackSize=0x400
ProjectManager.TargetToolchain=MDK-ARM V5
RCC.48MHZClocksFreq_Value=84000000
RCC.AHBFreq_Value=168000000
RCC.APB1CLKDivider=RCC_HCLK_DIV4
RCC.APB1Freq_Value=42000000
RCC.APB1TimFreq_Value=84000000
RCC.APB2CLKDivider=RCC_HCLK_DIV2
RCC.APB2Freq_Value=84000000
RCC.APB2TimFreq_Value=168000000
RCC.CortexFreq_Value=168000000
RCC.EnbaleCSS=true
RCC.HCLKFreq_Value=168000000
RCC.HSE_VALUE=8000000
RCC.HSI_VALUE=16000000
RCC.LSE_VALUE=32768
RCC.PLLM=4
RCC.PLLN=168
RCC.PLLSourceVirtual=RCC_PLLSOURCE_HSE
RCC.SYSCLKFreq_VALUE=168000000
RCC.SYSCLKSource=RCC_SYSCLKSOURCE_PLLCLK
RCC.VCOOutputFreq_Value=336000000
SH.ADCx_IN10.0=ADC1_IN10,IN10
SH.ADCx_IN13.0=ADC1_IN13,IN13
SH.COMP_DAC1_group.0=DAC_OUT1,DAC_OUT1
SH.COMP_DAC2_group.0=DAC_OUT2,DAC_OUT2
SH.S_TIM2_CH1_ETR.0=TIM2_CH1,Encoder_Interface
SH.S_TIM2_CH2.0=TIM2_CH2,Encoder_Interface
SH.S_TIM3_CH1.0=TIM3_CH1,Encoder_Interface
SH.S_TIM3_CH2.0=TIM3_CH2,Encoder_Interface
SH.S_TIM8_CH1.0=TIM8_CH1,PWM Generation1 CH1 CH1N
SH.S_TIM8_CH2.0=TIM8_CH2,PWM Generation2 CH2 CH2N
SH.S_TIM8_CH3.0=TIM8_CH3,PWM Generation3 CH3 CH3N
SH.SharedAnalog_PA6.0=ADC1_IN6,IN6
SH.SharedAnalog_PA6.1=ADC2_IN6,IN6
SH.SharedAnalog_PB0.0=ADC1_IN8,IN8
SH.SharedAnalog_PB0.1=ADC2_IN8,IN8
SH.SharedAnalog_PB1.0=ADC1_IN9,IN9
SH.SharedAnalog_PB1.1=ADC2_IN9,IN9
TIM2.EncoderMode=TIM_ENCODERMODE_TI12
TIM2.IC1Filter=M1_ENC_IC_FILTER
TIM2.IC1Polarity=TIM_ICPOLARITY_RISING
TIM2.IC2Filter=M1_ENC_IC_FILTER
TIM2.IC2Polarity=TIM_ICPOLARITY_RISING
TIM2.Period=M1_PULSE_NBR
TIM3.EncoderMode=TIM_ENCODERMODE_TI12
TIM3.Period=0xFFFF
TIM8.BreakPolarity=TIM_BREAKPOLARITY_LOW
TIM8.Channel-PWM\ Generation1\ CH1\ CH1N=TIM_CHANNEL_1
TIM8.Channel-PWM\ Generation2\ CH2\ CH2N=TIM_CHANNEL_2
TIM8.Channel-PWM\ Generation3\ CH3\ CH3N=TIM_CHANNEL_3
TIM8.Channel-PWM\ Generation4\ No\ Output=TIM_CHANNEL_4
TIM8.ClockDivision=TIM_CLOCKDIVISION_DIV2
TIM8.CounterMode=TIM_COUNTERMODE_CENTERALIGNED1
TIM8.DeadTime=((DEAD_TIME_COUNTS) / 2)
TIM8.LockLevel=TIM_LOCKLEVEL_1
TIM8.OCIdleState_1=TIM_OCIDLESTATE_RESET
TIM8.OCIdleState_2=TIM_OCIDLESTATE_RESET
TIM8.OCIdleState_3=TIM_OCIDLESTATE_RESET
TIM8.OCMode_PWM-PWM\ Generation4\ No\ Output=TIM_OCMODE_PWM2
TIM8.OCNIdleState_1=TIM_OCNIDLESTATE_RESET
TIM8.OCNIdleState_2=TIM_OCNIDLESTATE_RESET
TIM8.OCNIdleState_3=TIM_OCNIDLESTATE_RESET
TIM8.OCNPolarity_1=TIM_OCNPOLARITY_HIGH
TIM8.OCNPolarity_2=TIM_OCNPOLARITY_HIGH
TIM8.OCNPolarity_3=TIM_OCNPOLARITY_HIGH
TIM8.OCPolarity_1=TIM_OCPOLARITY_HIGH
TIM8.OCPolarity_2=TIM_OCPOLARITY_HIGH
TIM8.OCPolarity_3=TIM_OCPOLARITY_HIGH
TIM8.OffStateIDLEMode=TIM_OSSI_ENABLE
TIM8.OffStateRunMode=TIM_OSSR_ENABLE
TIM8.Period=((PWM_PERIOD_CYCLES) / 2)
TIM8.Prescaler=((TIM_CLOCK_DIVIDER) - 1)
TIM8.Pulse-PWM\ Generation1\ CH1=((PWM_PERIOD_CYCLES) / 4)
TIM8.Pulse-PWM\ Generation2\ CH2=((PWM_PERIOD_CYCLES) / 4)
TIM8.Pulse-PWM\ Generation3\ CH3=((PWM_PERIOD_CYCLES) / 4)
TIM8.Pulse-PWM\ Generation4\ No\ Output=(((PWM_PERIOD_CYCLES) / 2) - (HTMIN))
TIM8.RepetitionCounter=(REP_COUNTER)
TIM8.TIM_MasterOutputTrigger=TIM_TRGO_RESET
UART5.VirtualMode=Asynchronous
USART1.BaudRate=115200
USART1.VirtualMode=VM_ASYNC
USART1.VirtualMode-Asynchronous=VM_ASYNC
USART1.WordLength=WORDLENGTH_8B
VP_MotorControl_MC_ENABLED.Mode=Enabled
VP_TIM8_VS_ClockSourceITR.Mode=TriggerSource_ITR1
VP_TIM8_VS_ControllerModeTrigger.Mode=Trigger Mode
VP_TIM8_VS_no_output4.Mode=PWM Generation4 No Output
board=custom

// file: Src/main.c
/* USER CODE BEGIN Header */
/**
  ******************************************************************************
  * @file           : main.c
  * @brief          : Main program body
  ******************************************************************************
  * @attention
  *
  * <h2><center>&copy; Copyright (c) 2022 STMicroelectronics.
  * All rights reserved.</center></h2>
  *
  * This software component is licensed by ST under Ultimate Liberty license
  * SLA0044, the "License"; You may not use this file except in compliance with
  * the License. You may obtain a copy of the License at:
  *                             www.st.com/SLA0044
  *
  ******************************************************************************
  */
/* USER CODE END Header */

#include "main.h"
#include "motorcontrol.h"

/* USER CODE BEGIN Includes */
#include <stdlib.h>
#include <stdio.h>
#include <math.h>
#include <string.h>
/* USER CODE END Includes */

/* USER CODE BEGIN PD */
#define ENCODER_RULER_TIM_PERIOD 65535
#define GO_HOME_SPEED 400

#define delay_time 10
// #define control_delay 1

/* USER CODE END PD */

ADC_HandleTypeDef hadc1;
ADC_HandleTypeDef hadc2;

DAC_HandleTypeDef hdac;

TIM_HandleTypeDef htim2;
TIM_HandleTypeDef htim3;
TIM_HandleTypeDef htim8;

UART_HandleTypeDef huart5;
UART_HandleTypeDef huart1;

/* USER CODE BEGIN PV */

// 定义存储与该算法相关变量的结构体
typedef struct
{
    unsigned int t_0; /* t0信号发送器开始工作的时刻, 单位s */
    unsigned int t_01; /* 从t0到t1的时间间隔, 单位s */
    float f0; /* 时刻t0对应的频率， 单位hz */
    float f1; /* 时刻t1对应的频率， 单位hz */
    float k; /* 指数函数的底数 */
    float p; /* 系数 p */
    float A; /* 扫频信号的幅值 */
} my_sweep_t;

typedef struct
{
    uint8_t start_flag;
    uint8_t frame_len;
    uint8_t header_check;
    uint8_t data_buf[12];
    uint8_t frame_check;
} frame_matlab_t;

// 光栅尺溢出记数
int encoder_ruler_overflow_count = 0;

/// @brief  状态变量 0 对应没有启动，1 对应开始启动未到达左端，2 对应到达左端后向右运动且未到达右端， 3对应到达右端后开始回正， 4 对应回到了中间位置并停止
int start_status = 0;

float now_position = 0;

float left_position = 0, right_position = 0;
float mid_position = 0;

float limit_position = 2;

int find_home_flag = 0;

int function_mode = 1; // 1为阶跃测试，2为扫频测试
int function_start = 0;

// my_sweep_t sweep;

// sweep = {
//     .t_0 = 0,
//     .t_01 = 0,
//     .f0 = 0,
//     .f1 = 0,
//     .k = 0,
//     .p = 0,
//     .A = 0
// };

volatile uint8_t step_init_flag = 0;      // 阶跃测试初始化标志
volatile uint8_t chirp_init_flag = 0;     // 扫频测试初始化标志
volatile float error = 0.0f;              // 当前误差
volatile float last_error = 0.0f;         // 上一次误差
volatile float control = 0.0f;            // 控制量
volatile float last_control = 0.0f;       // 上一次控制量
volatile int16_t control_int = 0;         // 控制量整型值
volatile float pos = 0.0f;                // 当前位置
volatile float ref = 0.0f;                // 目标位置
volatile uint8_t test_mode = 1;           // 测试模式（0:无测试，1:阶跃测试，2:扫频测试）

/* USER CODE END PV */

void SystemClock_Config(void);
static void MX_GPIO_Init(void);
static void MX_ADC1_Init(void);
static void MX_ADC2_Init(void);
static void MX_DAC_Init(void);
static void MX_TIM2_Init(void);
static void MX_TIM8_Init(void);
static void MX_USART1_UART_Init(void);
static void MX_TIM3_Init(void);
static void MX_UART5_Init(void);
static void MX_NVIC_Init(void);
/* USER CODE BEGIN PFP */

int fputc(int ch, FILE *f)
{
    HAL_UART_Transmit(&huart5, (uint8_t *)&ch, 1, 0xffff);
    return ch;
}
int fgetc(FILE *f)
{
    uint8_t ch = 0;
    HAL_UART_Receive(&huart5, &ch, 1, 0xffff);
    return ch;
}

int init_my_sweep(my_sweep_t *sweep, unsigned int t_0, unsigned int t_01, float f0, float f1, float A);
float run_my_sweep(my_sweep_t *sweep, unsigned int t_now);
uint8_t get_uint8_sum_check(uint8_t *data, int len);
void  send_data_2_matlab(float data1, float data2, float data3);
void function_sweep_identification(void);

float Get_Encoder_Ruler_Count(void);
void HAL_TIM_PeriodElapsedCallback(TIM_HandleTypeDef *htim);
void my_motor_control(void);

void function_step_test(void);
void function_sweep_follow_test(void);

/* USER CODE END PFP */

int main(void)
{

  /* MCU Configuration--------------------------------------------------------*/

  /* Reset of all peripherals, Initializes the Flash interface and the Systick. */
  HAL_Init();

  /* Configure the system clock */
  SystemClock_Config();

  /* Initialize all configured peripherals */
  MX_GPIO_Init();
  MX_ADC1_Init();
  MX_ADC2_Init();
  MX_DAC_Init();
  MX_TIM2_Init();
  MX_TIM8_Init();
  MX_USART1_UART_Init();
  MX_TIM3_Init();
  MX_UART5_Init();
    MX_MotorControl_Init();

  /* Initialize interrupts */
  MX_NVIC_Init();
  /* USER CODE BEGIN 2 */

    //! 初始化
    HAL_TIM_Encoder_Start(&htim3,TIM_CHANNEL_ALL);
    MC_AlignEncoderMotor1();
    HAL_Delay(1000);

    //使能溢出中断
    __HAL_TIM_CLEAR_IT(&htim3, TIM_IT_UPDATE);
    __HAL_TIM_URS_ENABLE(&htim3);
    __HAL_TIM_ENABLE_IT(&htim3,TIM_IT_UPDATE);

    // MC_StartMotor1();
    HAL_Delay(1000);

    //先回零（根据情况加入）
    // while(find_home_flag != 1)
    // {
    //     my_motor_control();
    //     HAL_Delay(100);
    // }
    MC_StartMotor1();
    MC_ProgramSpeedRampMotor1(0,0); //! 很奇怪，一定要加才能启动运行

    // //扫频
    HAL_Delay(1000);
    find_home_flag = 1;
    // start_status = 1;
    while(function_start != 1)
    {
        HAL_Delay(100);
    }

  /* USER CODE END 2 */

  /* Infinite loop */
  while (1)
  {

    /* USER CODE BEGIN 3 */

    //对电机进行控制

    switch(function_mode)
    {
        case 1: //阶跃测试
            function_step_test();
            break;
        case 2: //扫频测试
            function_sweep_follow_test();
            break;
        default:
            break;
    }

    // function_sweep_follow_test();

  }
  /* USER CODE END 3 */
}

void SystemClock_Config(void)
{
  RCC_OscInitTypeDef RCC_OscInitStruct = {0};
  RCC_ClkInitTypeDef RCC_ClkInitStruct = {0};

  /** Configure the main internal regulator output voltage
  */
  __HAL_RCC_PWR_CLK_ENABLE();
  __HAL_PWR_VOLTAGESCALING_CONFIG(PWR_REGULATOR_VOLTAGE_SCALE1);
  /** Initializes the CPU, AHB and APB busses clocks
  */
  RCC_OscInitStruct.OscillatorType = RCC_OSCILLATORTYPE_HSE;
  RCC_OscInitStruct.HSEState = RCC_HSE_ON;
  RCC_OscInitStruct.PLL.PLLState = RCC_PLL_ON;
  RCC_OscInitStruct.PLL.PLLSource = RCC_PLLSOURCE_HSE;
  RCC_OscInitStruct.PLL.PLLM = 4;
  RCC_OscInitStruct.PLL.PLLN = 168;
  RCC_OscInitStruct.PLL.PLLP = RCC_PLLP_DIV2;
  RCC_OscInitStruct.PLL.PLLQ = 4;
  if (HAL_RCC_OscConfig(&RCC_OscInitStruct) != HAL_OK)
  {
    Error_Handler();
  }
  /** Initializes the CPU, AHB and APB busses clocks
  */
  RCC_ClkInitStruct.ClockType = RCC_CLOCKTYPE_HCLK|RCC_CLOCKTYPE_SYSCLK
                              |RCC_CLOCKTYPE_PCLK1|RCC_CLOCKTYPE_PCLK2;
  RCC_ClkInitStruct.SYSCLKSource = RCC_SYSCLKSOURCE_PLLCLK;
  RCC_ClkInitStruct.AHBCLKDivider = RCC_SYSCLK_DIV1;
  RCC_ClkInitStruct.APB1CLKDivider = RCC_HCLK_DIV4;
  RCC_ClkInitStruct.APB2CLKDivider = RCC_HCLK_DIV2;

  if (HAL_RCC_ClockConfig(&RCC_ClkInitStruct, FLASH_LATENCY_5) != HAL_OK)
  {
    Error_Handler();
  }
  /** Enables the Clock Security System
  */
  HAL_RCC_EnableCSS();
}

/**
  * @brief NVIC Configuration.
  * @retval None
  */
static void MX_NVIC_Init(void)
{
  /* ADC_IRQn interrupt configuration */
  HAL_NVIC_SetPriority(ADC_IRQn, 2, 0);
  HAL_NVIC_EnableIRQ(ADC_IRQn);
  /* TIM8_UP_TIM13_IRQn interrupt configuration */
  HAL_NVIC_SetPriority(TIM8_UP_TIM13_IRQn, 0, 0);
  HAL_NVIC_EnableIRQ(TIM8_UP_TIM13_IRQn);
  /* TIM8_BRK_TIM12_IRQn interrupt configuration */
  HAL_NVIC_SetPriority(TIM8_BRK_TIM12_IRQn, 4, 1);
  HAL_NVIC_EnableIRQ(TIM8_BRK_TIM12_IRQn);
  /* TIM2_IRQn interrupt configuration */
  HAL_NVIC_SetPriority(TIM2_IRQn, 3, 0);
  HAL_NVIC_EnableIRQ(TIM2_IRQn);
  /* USART1_IRQn interrupt configuration */
  HAL_NVIC_SetPriority(USART1_IRQn, 3, 1);
  HAL_NVIC_EnableIRQ(USART1_IRQn);
  /* EXTI0_IRQn interrupt configuration */
  HAL_NVIC_SetPriority(EXTI0_IRQn, 0, 0);
  HAL_NVIC_EnableIRQ(EXTI0_IRQn);
}

static void MX_ADC1_Init(void)
{

  ADC_InjectionConfTypeDef sConfigInjected = {0};
  ADC_ChannelConfTypeDef sConfig = {0};

  /** Configure the global features of the ADC (Clock, Resolution, Data Alignment and number of conversion)
  */
  hadc1.Instance = ADC1;
  hadc1.Init.ClockPrescaler = ADC_CLOCK_SYNC_PCLK_DIV4;
  hadc1.Init.Resolution = ADC_RESOLUTION_12B;
  hadc1.Init.ScanConvMode = ENABLE;
  hadc1.Init.ContinuousConvMode = DISABLE;
  hadc1.Init.DiscontinuousConvMode = DISABLE;
  hadc1.Init.ExternalTrigConvEdge = ADC_EXTERNALTRIGCONVEDGE_NONE;
  hadc1.Init.ExternalTrigConv = ADC_SOFTWARE_START;
  hadc1.Init.DataAlign = ADC_DATAALIGN_LEFT;
  hadc1.Init.NbrOfConversion = 2;
  hadc1.Init.DMAContinuousRequests = DISABLE;
  hadc1.Init.EOCSelection = ADC_EOC_SINGLE_CONV;
  if (HAL_ADC_Init(&hadc1) != HAL_OK)
  {
    Error_Handler();
  }
  /** Configures for the selected ADC injected channel its corresponding rank in the sequencer and its sample time
  */
  sConfigInjected.InjectedChannel = ADC_CHANNEL_6;
  sConfigInjected.InjectedRank = 1;
  sConfigInjected.InjectedNbrOfConversion = 3;
  sConfigInjected.InjectedSamplingTime = ADC_SAMPLETIME_3CYCLES;
  sConfigInjected.ExternalTrigInjecConvEdge = ADC_EXTERNALTRIGINJECCONVEDGE_RISING;
  sConfigInjected.ExternalTrigInjecConv = ADC_EXTERNALTRIGINJECCONV_T8_CC4;
  sConfigInjected.AutoInjectedConv = DISABLE;
  sConfigInjected.InjectedDiscontinuousConvMode = ENABLE;
  sConfigInjected.InjectedOffset = 0;
  if (HAL_ADCEx_InjectedConfigChannel(&hadc1, &sConfigInjected) != HAL_OK)
  {
    Error_Handler();
  }
  /** Configures for the selected ADC injected channel its corresponding rank in the sequencer and its sample time
  */
  sConfigInjected.InjectedChannel = ADC_CHANNEL_8;
  if (HAL_ADCEx_InjectedConfigChannel(&hadc1, &sConfigInjected) != HAL_OK)
  {
    Error_Handler();
  }
  /** Configures for the selected ADC injected channel its corresponding rank in the sequencer and its sample time
  */
  sConfigInjected.InjectedChannel = ADC_CHANNEL_9;
  if (HAL_ADCEx_InjectedConfigChannel(&hadc1, &sConfigInjected) != HAL_OK)
  {
    Error_Handler();
  }
  /** Configure for the selected ADC regular channel its corresponding rank in the sequencer and its sample time.
  */
  sConfig.Channel = ADC_CHANNEL_10;
  sConfig.Rank = 1;
  sConfig.SamplingTime = ADC_SAMPLETIME_56CYCLES;
  sConfig.Offset = 0;

  if (HAL_ADC_ConfigChannel(&hadc1, &sConfig) != HAL_OK)
  {
    Error_Handler();
  }
  /** Configure for the selected ADC regular channel its corresponding rank in the sequencer and its sample time.
  */
  sConfig.Channel = ADC_CHANNEL_13;
  sConfig.Rank = 2;
  sConfig.SamplingTime = ADC_SAMPLETIME_28CYCLES;
  sConfig.Offset = 0;

  if (HAL_ADC_ConfigChannel(&hadc1, &sConfig) != HAL_OK)
  {
    Error_Handler();
  }

}

static void MX_ADC2_Init(void)
{

  ADC_InjectionConfTypeDef sConfigInjected = {0};
  ADC_ChannelConfTypeDef sConfig = {0};

  /** Configure the global features of the ADC (Clock, Resolution, Data Alignment and number of conversion)
  */
  hadc2.Instance = ADC2;
  hadc2.Init.ClockPrescaler = ADC_CLOCK_SYNC_PCLK_DIV4;
  hadc2.Init.Resolution = ADC_RESOLUTION_12B;
  hadc2.Init.ScanConvMode = ENABLE;
  hadc2.Init.ContinuousConvMode = DISABLE;
  hadc2.Init.DiscontinuousConvMode = DISABLE;
  hadc2.Init.ExternalTrigConvEdge = ADC_EXTERNALTRIGCONVEDGE_NONE;
  hadc2.Init.ExternalTrigConv = ADC_SOFTWARE_START;
  hadc2.Init.DataAlign = ADC_DATAALIGN_LEFT;
  hadc2.Init.NbrOfConversion = 1;
  hadc2.Init.DMAContinuousRequests = DISABLE;
  hadc2.Init.EOCSelection = ADC_EOC_SINGLE_CONV;
  if (HAL_ADC_Init(&hadc2) != HAL_OK)
  {
    Error_Handler();
  }
  /** Configures for the selected ADC injected channel its corresponding rank in the sequencer and its sample time
  */
  sConfigInjected.InjectedChannel = ADC_CHANNEL_6;
  sConfigInjected.InjectedRank = 1;
  sConfigInjected.InjectedNbrOfConversion = 3;
  sConfigInjected.InjectedSamplingTime = ADC_SAMPLETIME_3CYCLES;
  sConfigInjected.ExternalTrigInjecConvEdge = ADC_EXTERNALTRIGINJECCONVEDGE_RISING;
  sConfigInjected.ExternalTrigInjecConv = ADC_EXTERNALTRIGINJECCONV_T8_CC4;
  sConfigInjected.AutoInjectedConv = DISABLE;
  sConfigInjected.InjectedDiscontinuousConvMode = ENABLE;
  sConfigInjected.InjectedOffset = 0;
  if (HAL_ADCEx_InjectedConfigChannel(&hadc2, &sConfigInjected) != HAL_OK)
  {
    Error_Handler();
  }
  /** Configures for the selected ADC injected channel its corresponding rank in the sequencer and its sample time
  */
  sConfigInjected.InjectedChannel = ADC_CHANNEL_8;
  if (HAL_ADCEx_InjectedConfigChannel(&hadc2, &sConfigInjected) != HAL_OK)
  {
    Error_Handler();
  }
  /** Configures for the selected ADC injected channel its corresponding rank in the sequencer and its sample time
  */
  sConfigInjected.InjectedChannel = ADC_CHANNEL_9;
  if (HAL_ADCEx_InjectedConfigChannel(&hadc2, &sConfigInjected) != HAL_OK)
  {
    Error_Handler();
  }
  /** Configure for the selected ADC regular channel its corresponding rank in the sequencer and its sample time.
  */
  sConfig.Channel = ADC_CHANNEL_6;
  sConfig.Rank = 1;
  sConfig.SamplingTime = ADC_SAMPLETIME_3CYCLES;
  if (HAL_ADC_ConfigChannel(&hadc2, &sConfig) != HAL_OK)
  {
    Error_Handler();
  }

}

static void MX_DAC_Init(void)
{

  DAC_ChannelConfTypeDef sConfig = {0};

  /** DAC Initialization
  */
  hdac.Instance = DAC;
  if (HAL_DAC_Init(&hdac) != HAL_OK)
  {
    Error_Handler();
  }
  /** DAC channel OUT1 config
  */
  sConfig.DAC_Trigger = DAC_TRIGGER_SOFTWARE;
  sConfig.DAC_OutputBuffer = DAC_OUTPUTBUFFER_DISABLE;
  if (HAL_DAC_ConfigChannel(&hdac, &sConfig, DAC_CHANNEL_1) != HAL_OK)
  {
    Error_Handler();
  }
  /** DAC channel OUT2 config
  */
  if (HAL_DAC_ConfigChannel(&hdac, &sConfig, DAC_CHANNEL_2) != HAL_OK)
  {
    Error_Handler();
  }

}

static void MX_TIM2_Init(void)
{

  TIM_Encoder_InitTypeDef sConfig = {0};
  TIM_MasterConfigTypeDef sMasterConfig = {0};

  htim2.Instance = TIM2;
  htim2.Init.Prescaler = 0;
  htim2.Init.CounterMode = TIM_COUNTERMODE_UP;
  htim2.Init.Period = M1_PULSE_NBR;
  htim2.Init.ClockDivision = TIM_CLOCKDIVISION_DIV1;
  htim2.Init.AutoReloadPreload = TIM_AUTORELOAD_PRELOAD_DISABLE;
  sConfig.EncoderMode = TIM_ENCODERMODE_TI12;
  sConfig.IC1Polarity = TIM_ICPOLARITY_RISING;
  sConfig.IC1Selection = TIM_ICSELECTION_DIRECTTI;
  sConfig.IC1Prescaler = TIM_ICPSC_DIV1;
  sConfig.IC1Filter = M1_ENC_IC_FILTER;
  sConfig.IC2Polarity = TIM_ICPOLARITY_RISING;
  sConfig.IC2Selection = TIM_ICSELECTION_DIRECTTI;
  sConfig.IC2Prescaler = TIM_ICPSC_DIV1;
  sConfig.IC2Filter = M1_ENC_IC_FILTER;
  if (HAL_TIM_Encoder_Init(&htim2, &sConfig) != HAL_OK)
  {
    Error_Handler();
  }
  sMasterConfig.MasterOutputTrigger = TIM_TRGO_RESET;
  sMasterConfig.MasterSlaveMode = TIM_MASTERSLAVEMODE_DISABLE;
  if (HAL_TIMEx_MasterConfigSynchronization(&htim2, &sMasterConfig) != HAL_OK)
  {
    Error_Handler();
  }

}

static void MX_TIM3_Init(void)
{

  TIM_Encoder_InitTypeDef sConfig = {0};
  TIM_MasterConfigTypeDef sMasterConfig = {0};

  htim3.Instance = TIM3;
  htim3.Init.Prescaler = 0;
  htim3.Init.CounterMode = TIM_COUNTERMODE_UP;
  htim3.Init.Period = 0xFFFF;
  htim3.Init.ClockDivision = TIM_CLOCKDIVISION_DIV1;
  htim3.Init.AutoReloadPreload = TIM_AUTORELOAD_PRELOAD_DISABLE;
  sConfig.EncoderMode = TIM_ENCODERMODE_TI12;
  sConfig.IC1Polarity = TIM_ICPOLARITY_RISING;
  sConfig.IC1Selection = TIM_ICSELECTION_DIRECTTI;
  sConfig.IC1Prescaler = TIM_ICPSC_DIV1;
  sConfig.IC1Filter = 0;
  sConfig.IC2Polarity = TIM_ICPOLARITY_RISING;
  sConfig.IC2Selection = TIM_ICSELECTION_DIRECTTI;
  sConfig.IC2Prescaler = TIM_ICPSC_DIV1;
  sConfig.IC2Filter = 0;
  if (HAL_TIM_Encoder_Init(&htim3, &sConfig) != HAL_OK)
  {
    Error_Handler();
  }
  sMasterConfig.MasterOutputTrigger = TIM_TRGO_RESET;
  sMasterConfig.MasterSlaveMode = TIM_MASTERSLAVEMODE_DISABLE;
  if (HAL_TIMEx_MasterConfigSynchronization(&htim3, &sMasterConfig) != HAL_OK)
  {
    Error_Handler();
  }

}

static void MX_TIM8_Init(void)
{

  TIM_SlaveConfigTypeDef sSlaveConfig = {0};
  TIM_MasterConfigTypeDef sMasterConfig = {0};
  TIM_OC_InitTypeDef sConfigOC = {0};
  TIM_BreakDeadTimeConfigTypeDef sBreakDeadTimeConfig = {0};

  htim8.Instance = TIM8;
  htim8.Init.Prescaler = ((TIM_CLOCK_DIVIDER) - 1);
  htim8.Init.CounterMode = TIM_COUNTERMODE_CENTERALIGNED1;
  htim8.Init.Period = ((PWM_PERIOD_CYCLES) / 2);
  htim8.Init.ClockDivision = TIM_CLOCKDIVISION_DIV2;
  htim8.Init.RepetitionCounter = (REP_COUNTER);
  htim8.Init.AutoReloadPreload = TIM_AUTORELOAD_PRELOAD_DISABLE;
  if (HAL_TIM_Base_Init(&htim8) != HAL_OK)
  {
    Error_Handler();
  }
  if (HAL_TIM_PWM_Init(&htim8) != HAL_OK)
  {
    Error_Handler();
  }
  sSlaveConfig.SlaveMode = TIM_SLAVEMODE_TRIGGER;
  sSlaveConfig.InputTrigger = TIM_TS_ITR1;
  if (HAL_TIM_SlaveConfigSynchro(&htim8, &sSlaveConfig) != HAL_OK)
  {
    Error_Handler();
  }
  sMasterConfig.MasterOutputTrigger = TIM_TRGO_RESET;
  sMasterConfig.MasterSlaveMode = TIM_MASTERSLAVEMODE_DISABLE;
  if (HAL_TIMEx_MasterConfigSynchronization(&htim8, &sMasterConfig) != HAL_OK)
  {
    Error_Handler();
  }
  sConfigOC.OCMode = TIM_OCMODE_PWM1;
  sConfigOC.Pulse = 0;
  sConfigOC.OCPolarity = TIM_OCPOLARITY_HIGH;
  sConfigOC.OCNPolarity = TIM_OCNPOLARITY_HIGH;
  sConfigOC.OCFastMode = TIM_OCFAST_DISABLE;
  sConfigOC.OCIdleState = TIM_OCIDLESTATE_RESET;
  sConfigOC.OCNIdleState = TIM_OCNIDLESTATE_RESET;
  if (HAL_TIM_PWM_ConfigChannel(&htim8, &sConfigOC, TIM_CHANNEL_1) != HAL_OK)
  {
    Error_Handler();
  }
  if (HAL_TIM_PWM_ConfigChannel(&htim8, &sConfigOC, TIM_CHANNEL_2) != HAL_OK)
  {
    Error_Handler();
  }
  if (HAL_TIM_PWM_ConfigChannel(&htim8, &sConfigOC, TIM_CHANNEL_3) != HAL_OK)
  {
    Error_Handler();
  }
  sConfigOC.OCMode = TIM_OCMODE_PWM2;
  sConfigOC.Pulse = (((PWM_PERIOD_CYCLES) / 2) - (HTMIN));
  if (HAL_TIM_PWM_ConfigChannel(&htim8, &sConfigOC, TIM_CHANNEL_4) != HAL_OK)
  {
    Error_Handler();
  }
  sBreakDeadTimeConfig.OffStateRunMode = TIM_OSSR_ENABLE;
  sBreakDeadTimeConfig.OffStateIDLEMode = TIM_OSSI_ENABLE;
  sBreakDeadTimeConfig.LockLevel = TIM_LOCKLEVEL_1;
  sBreakDeadTimeConfig.DeadTime = ((DEAD_TIME_COUNTS) / 2);
  sBreakDeadTimeConfig.BreakState = TIM_BREAK_DISABLE;
  sBreakDeadTimeConfig.BreakPolarity = TIM_BREAKPOLARITY_LOW;
  sBreakDeadTimeConfig.AutomaticOutput = TIM_AUTOMATICOUTPUT_DISABLE;
  if (HAL_TIMEx_ConfigBreakDeadTime(&htim8, &sBreakDeadTimeConfig) != HAL_OK)
  {
    Error_Handler();
  }
  HAL_TIM_MspPostInit(&htim8);

}

static void MX_UART5_Init(void)
{

  huart5.Instance = UART5;
  huart5.Init.BaudRate = 115200;
  huart5.Init.WordLength = UART_WORDLENGTH_8B;
  huart5.Init.StopBits = UART_STOPBITS_1;
  huart5.Init.Parity = UART_PARITY_NONE;
  huart5.Init.Mode = UART_MODE_TX_RX;
  huart5.Init.HwFlowCtl = UART_HWCONTROL_NONE;
  huart5.Init.OverSampling = UART_OVERSAMPLING_16;
  if (HAL_UART_Init(&huart5) != HAL_OK)
  {
    Error_Handler();
  }

}

static void MX_USART1_UART_Init(void)
{

  huart1.Instance = USART1;
  huart1.Init.BaudRate = 115200;
  huart1.Init.WordLength = UART_WORDLENGTH_8B;
  huart1.Init.StopBits = UART_STOPBITS_1;
  huart1.Init.Parity = UART_PARITY_NONE;
  huart1.Init.Mode = UART_MODE_TX_RX;
  huart1.Init.HwFlowCtl = UART_HWCONTROL_NONE;
  huart1.Init.OverSampling = UART_OVERSAMPLING_16;
  if (HAL_UART_Init(&huart1) != HAL_OK)
  {
    Error_Handler();
  }

}

static void MX_GPIO_Init(void)
{
  GPIO_InitTypeDef GPIO_InitStruct = {0};

  /* GPIO Ports Clock Enable */
  __HAL_RCC_GPIOE_CLK_ENABLE();
  __HAL_RCC_GPIOB_CLK_ENABLE();
  __HAL_RCC_GPIOC_CLK_ENABLE();
  __HAL_RCC_GPIOA_CLK_ENABLE();
  __HAL_RCC_GPIOI_CLK_ENABLE();
  __HAL_RCC_GPIOD_CLK_ENABLE();
  __HAL_RCC_GPIOH_CLK_ENABLE();
  __HAL_RCC_GPIOG_CLK_ENABLE();

  /*Configure GPIO pin : GoHome_Pin */
  GPIO_InitStruct.Pin = GoHome_Pin;
  GPIO_InitStruct.Mode = GPIO_MODE_IT_RISING;
  GPIO_InitStruct.Pull = GPIO_NOPULL;
  HAL_GPIO_Init(GoHome_GPIO_Port, &GPIO_InitStruct);

  /*Configure GPIO pin : Start_Stop_Pin */
  GPIO_InitStruct.Pin = Start_Stop_Pin;
  GPIO_InitStruct.Mode = GPIO_MODE_IT_FALLING;
  GPIO_InitStruct.Pull = GPIO_NOPULL;
  HAL_GPIO_Init(Start_Stop_GPIO_Port, &GPIO_InitStruct);

  /*Configure GPIO pins : LIM_P_Pin LIM_N_Pin */
  GPIO_InitStruct.Pin = LIM_P_Pin|LIM_N_Pin;
  GPIO_InitStruct.Mode = GPIO_MODE_INPUT;
  GPIO_InitStruct.Pull = GPIO_NOPULL;
  HAL_GPIO_Init(GPIOG, &GPIO_InitStruct);

  /* EXTI interrupt init*/
  HAL_NVIC_SetPriority(EXTI1_IRQn, 0, 0);
  HAL_NVIC_EnableIRQ(EXTI1_IRQn);

}

/* USER CODE BEGIN 4 */

// TIM中断回调函数中查询溢出状态
void HAL_TIM_PeriodElapsedCallback(TIM_HandleTypeDef *htim)
{
    if(htim->Instance == TIM3)
    {
        if(__HAL_TIM_IS_TIM_COUNTING_DOWN(&htim3))
        {
            encoder_ruler_overflow_count--;
        }
        else
        {
            encoder_ruler_overflow_count++;
        }
    }
}

/// @brief GPIO中断回调函数,按下按键后触发回零
/// @param GPIO_Pin
void HAL_GPIO_EXTI_Callback(uint16_t GPIO_Pin)
{
    if(GPIO_Pin == GoHome_Pin)
    {
        printf("handle_gohome_test: start\n");
        if(HAL_GPIO_ReadPin(GoHome_GPIO_Port,GoHome_Pin) == GPIO_PIN_RESET && start_status == 0)
        {
            int16_t  hFinalSpeed = GO_HOME_SPEED/6;
            uint16_t hDurationms = 0;

            function_start = 1; //开始进行step或者辨识
            start_status = 1;
        }
    }
}

/// @brief 获取光栅尺位置的代码
/// @param
/// @return 光栅尺位置，单位mm
float Get_Encoder_Ruler_Count(void)
{
    int32_t CaptureNumber = 0;
    float   ruler_pos = 0.0f;  //mm

    uint32_t Value = __HAL_TIM_GET_COUNTER(&htim3);
    int32_t Period = ENCODER_RULER_TIM_PERIOD + 1;

    CaptureNumber =  Value + encoder_ruler_overflow_count * Period;
    ruler_pos = (float)(CaptureNumber* 0.005f); //mm
    // printf("%ld,%ld,%ld,%f  end \n",Value,Period,CaptureNumber,ruler_pos);
    return ruler_pos;
}

/// @brief 电机回零控制函数
/// @param
void my_motor_control(void)
{

    now_position = Get_Encoder_Ruler_Count();
    printf("now: %.2f , mid: %f  \n",now_position,mid_position);

    if(start_status == 0) //不进行任何操作，等待按键GPIO中断触发，触发后start_status = 1,开始向左运动
    {

    }

    else if( start_status == 1) //正在向左运动，直到到达左限位
    {
        if(HAL_GPIO_ReadPin(LIM_P_GPIO_Port,LIM_P_Pin) == GPIO_PIN_RESET) //到达左限位，触发GPIO中断
        {
            left_position = now_position;
            start_status = 2; //切换状态，开始向右运动
            int16_t  hFinalSpeed = -GO_HOME_SPEED/6;
            uint16_t hDurationms = 0;
            MC_ProgramSpeedRampMotor1(hFinalSpeed,hDurationms);
            HAL_Delay(delay_time);
        }
    }

    else if( start_status == 2) //正在向右运动，直到到达右限位
    {
        if(HAL_GPIO_ReadPin(LIM_N_GPIO_Port,LIM_N_Pin) == GPIO_PIN_RESET) //到达右限位，触发GPIO中断
        {
            right_position = now_position;
            mid_position = left_position - (left_position - right_position) /2; //计算中点位置
            start_status = 3; //切换状态，开始回零
            int16_t  hFinalSpeed = GO_HOME_SPEED/6;
            uint16_t hDurationms = 0;
            MC_ProgramSpeedRampMotor1(hFinalSpeed,hDurationms);
            HAL_Delay(delay_time);
        }

    }

    else if( start_status == 3) //正在回零
    {
        //根据现在位置进行回零控制，在中点左侧则向右运动，在中点右侧则向左运动，在中点附近误差允许范围内则停止
        if(abs(now_position - mid_position) < limit_position)
        {
            MC_ProgramSpeedRampMotor1(0,0);
            start_status = 4;
            find_home_flag = 1;
        }
        else if( now_position < mid_position)
        {
            int16_t  hFinalSpeed = GO_HOME_SPEED/6;
            uint16_t hDurationms = 0;
            MC_ProgramSpeedRampMotor1(hFinalSpeed,hDurationms);
        }
        else if( now_position > mid_position)
        {
            int16_t  hFinalSpeed = -GO_HOME_SPEED/6;
            uint16_t hDurationms = 0;
            MC_ProgramSpeedRampMotor1(hFinalSpeed,hDurationms);
        }
        HAL_Delay(delay_time);

        // printf("now:%f,mid:%f \n",now_position,mid_position); //调试用的输出
    }
}

/// @brief 暂时废弃，等待完善
/// @param
void back_zero_function(void)
{
    if(abs(now_position - mid_position) < limit_position)
    {
        MC_StopMotor1();
    }
    else if( now_position > mid_position)
    {
        int16_t  hFinalSpeed = GO_HOME_SPEED/6;
        uint16_t hDurationms = 0;
        MC_ProgramSpeedRampMotor1(hFinalSpeed,hDurationms);
    }
    else if( now_position < mid_position)
    {
        int16_t  hFinalSpeed = -GO_HOME_SPEED/6;
        uint16_t hDurationms = 0;
        MC_ProgramSpeedRampMotor1(hFinalSpeed,hDurationms);
    }
}

/// @brief 扫频信号初始化函数
/// @param sweep 结构体，用于存储扫频信号的配置信息
/// @param t_0 信号发送器开始工作的时刻, 单位ms
/// @param t_01 从t0到t1的时间间隔, 单位ms
/// @param f0 时刻t0对应的频率， 单位hz
/// @param f1 时刻t1对应的频率， 单位hz
/// @param A 扫频信号的幅值
/// @return 0 = 成功， 其他表示异常
int init_my_sweep(my_sweep_t *sweep, unsigned int t_0, unsigned int t_01, float f0, float f1, float A)
{
    if ((t_01 == 0) || (f0 <= 0.0f) || (f1 <= 0.0f) || (f0 == f1) || (A == 0) || (!sweep))
    {
        return -1; /*非法入参*/
    }

    sweep->t_0 = t_0;
    sweep->t_01 = t_01;
    sweep->f0 = f0;
    sweep->f1 = f1;
    sweep->A = A;

    sweep->k = exp(1/(0.001*t_01)*log(f1/f0)); // 时间单位换算为秒
    sweep->p = 2* 3.14159265 * f0 /(log(sweep->k));

    return 0;
}

/// @brief 获取正弦扫频信号的函数
/// @param sweep 信号发生器结构体指针
/// @param t_now 当前时间 单位ms
/// @return 扫频信号
float run_my_sweep(my_sweep_t *sweep, unsigned int t_now)
{
    float t = 0.0f; //相对时间 t
    float y = 0.0f; //扫频信号

    // if (!sweep)
    // {
    //     return 0.0f; /*非法入参*/
    // }

    // if (t_now < sweep->t_0)
    // {
    //     return 0.0f; /*时间还未得到*/
    // }

    t = (t_now - sweep->t_0) * 0.001f;  // 转换为秒
    y = sweep->A * sin(2.0f * 3.14159265f * t);  // 2π * 1Hz * t

    return y;
}

/* 对 uint8_t 数值进行求和 ,获得这组数据一个uint8_t特征*/
uint8_t get_uint8_sum_check(uint8_t *data, int len)
{
    int i = 0;
    uint8_t sum = 0;
    for (i = 0; i < len; i++)
    {
        sum += data[i];
    }
    return sum;
}

/*
函数：send_data_2_matlab
功能：往matlab发送三个浮点数
输入：三个浮点数
输出：无
*/
void  send_data_2_matlab(float data1, float data2, float data3)
{
    frame_matlab_t  frame = {0};
    int i = 0;

    /*填充帧头*/
    frame.start_flag = 0xAA;
    frame.frame_len  = sizeof(frame);
    frame.header_check = get_uint8_sum_check((uint8_t *)&frame, 2);
    /*填充数据*/
    memcpy((uint8_t *)&frame.data_buf[0], (uint8_t *)&data1, 4);
    memcpy((uint8_t *)&frame.data_buf[4], (uint8_t *)&data2, 4);
    // 原代码未完整展示填充 data3 的部分，补充如下
    memcpy((uint8_t *)&frame.data_buf[8], (uint8_t *)&data3, 4);
    frame.frame_check = get_uint8_sum_check((uint8_t *)&frame, sizeof(frame));
    // 原代码未展示发送数据的部分，假设使用 HAL_UART_Transmit 函数发送
    HAL_UART_Transmit(&huart1, (uint8_t *)&frame, sizeof(frame), HAL_MAX_DELAY); //!!!!! 串口1？
}

/// @brief 扫频辨识功能
/// @param
void function_sweep_identification(void)
{
    static my_sweep_t sweep = {0};
    int16_t sweep_input = 0;
    int16_t sweep_output = 0;
    uint32_t sys_tick = 0;
    static uint32_t init_flag = 0;
    static uint32_t last_sys_tick = 0;
    static uint32_t start_sys_tick = 0;
    // 频率在10s内，从0.5hz变化到10hz，幅度为1500digitcurrent
    uint32_t t_period_ms = 10 * 1000; // 10s
    float f0 = 0.5;
    float f1 = 10;
    float Amp = 1700.0f;
    float time = 0.0f;
    sys_tick = HAL_GetTick(); // 获取当前时刻，单位ms
    time = 0.001f * sys_tick; // 单位s
    if ((find_home_flag == 1) && (MC_GetSTMStateMotor1() == RUN))
    {
        if (last_sys_tick != sys_tick) // 如果当前时刻发生了变化，这个条件每ms都会成立一次
        {
            last_sys_tick = sys_tick;
            if (sys_tick % 10 == 0) // 通过%把频率从1000hz降低到100hz，即每10ms发生一次
            {
                // 初始化扫频配置
                if (init_flag == 0)
                {
                    init_my_sweep(&sweep, sys_tick, t_period_ms, f0, f1, Amp);
                    printf("sweep-init:k=%.5f,p=%.5f\r\n", (float)sweep.k, (float)sweep.p);
                    init_flag = 1;
                }
                // 获取正弦扫频信号
                sweep_input = (int16_t)run_my_sweep(&sweep, sys_tick);
                // 将正弦扫频信号输入到STMCSDK的力矩控制API中
                MC_ProgramTorqueRampMotor1(sweep_input, 0);
                // 获取丝杆的转速信息，单位为0.1hz
                sweep_output = MC_GetMecSpeedAverageMotor1();
                // 把时间，input, output 发送到 matlab
                send_data_2_matlab(time, (float)sweep_input, (float)sweep_output);
            }
        }
    }
}

/// @brief 阶跃测试函数
/// @param
void function_step_test(void)
{
    static float u_prev = 0.0f;        // 上一次控制输出
    static float e_prev = 0.0f;        // 上一次误差
    static uint8_t step_init_flag = 0; // 阶跃是否已初始化
    static float ref = 0.0f;           // 参考值（目标位置）
    static uint32_t last_tick = 0;     // 上一次控制时间戳
    static uint32_t tick_start = 0;    // 控制器开始运行的时间戳

    float fdk = 0.0f;                  // 当前实际位置
    float e = 0.0f;                    // 当前误差
    float u = 0.0f;                    // 控制输出（浮点数）
    const float Amp = 20.0f;           // 阶跃幅值
    const uint32_t control_delay = 10; // 控制周期（单位ms）

    uint32_t current_tick = HAL_GetTick();
    float time = 0.0f;                 // 当前控制时间，单位s

    // 首次调用时的初始化
    if (step_init_flag == 0 && find_home_flag == 1)
    {
        fdk = Get_Encoder_Ruler_Count();  // 读取当前位置
        ref = fdk + Amp;                  // 设置目标值
        u_prev = 0.0f;
        e_prev = 0.0f;
        last_tick = current_tick;
        tick_start = current_tick; // 记录控制器开始运行的时间
        step_init_flag = 1;
    }

    if (step_init_flag == 1 && find_home_flag == 1)
    {
        if ((current_tick - last_tick) >= control_delay)
        {
            last_tick = current_tick;
            time = 0.001f * (current_tick - tick_start);  // 以控制启动为时间零点

            // 获取当前真实位置
            fdk = Get_Encoder_Ruler_Count();

            // 计算误差
            e = ref - fdk;

            // 根据所设计的控制器进行离散化实现
            u = 0.3679f * u_prev + 1200.0f * e - 883.9f * e_prev;

            // 更新状态
            u_prev = u;
            e_prev = e;

            // 限幅
            if (u > 4997.0f)
                u = 4997.0f;
            else if (u < -4997.0f)
                u = -4997.0f;

            int16_t output = (int16_t)u;

            // 输出控制指令（扭矩模式）
            MC_ProgramTorqueRampMotor1(output, 0);

            //将数据发送到MATLAB上位机分析
            send_data_2_matlab(time, ref,fdk);
        }
    }
}

/// @brief 正弦跟随测试函数
/// @param
void function_sweep_follow_test(void)
{
    static uint8_t sweep_init_flag = 0;
    static float u_prev = 0.0f;
    static float e_prev = 0.0f;
    static uint32_t last_tick = 0;
    static my_sweep_t sweep_param;

    float ref = 0.0f;
    float fdk = 0.0f;
    float e = 0.0f;
    float u = 0.0f;
    uint32_t current_tick = 0;
    const uint32_t control_delay = 10;
    static float start_tick = 0;
    static float origin_position = 0;

    if (sweep_init_flag == 0)
    {
        u_prev = 0.0f;
        e_prev = 0.0f;
        last_tick = HAL_GetTick();
        sweep_init_flag = 1;
        start_tick = last_tick; // 记录控制器开始运行的时间
        origin_position = Get_Encoder_Ruler_Count(); // 获取光栅尺的初始位置
    }

    if (find_home_flag == 1 && sweep_init_flag == 1)
    {
        current_tick = HAL_GetTick();
        if (current_tick - last_tick >= control_delay)
        {
            last_tick = current_tick;

            // 获取当前真实位置
            fdk = Get_Encoder_Ruler_Count();

            float t = 0.001f*(current_tick - start_tick); // 将ms转换为s
            ref = origin_position + 20.0f* sin (2.0f * 3.14159265f * t); // 生成正弦波参考信号，幅值为20mm，频率为1Hz

            // 计算误差
            e = ref - fdk;

            // 根据所设计的控制器进行离散化实现
            u = 0.3679f * u_prev + 1200.0f * e - 883.9f * e_prev;

            // 更新状态
            u_prev = u;
            e_prev = e;

            // 限幅
            if (u > 4997)
                u = 4997;
            else if (u < -4997)
                u = -4997;

            int16_t output = (int16_t)u;

            // 输出控制指令（扭矩模式）
            MC_ProgramTorqueRampMotor1(output, 0);

            //将数据发送到MATLAB上位机分析
            send_data_2_matlab((float)(current_tick-start_tick) * 0.001f, ref, fdk);
        }
    }
}

/* USER CODE END 4 */

void Error_Handler(void)
{
}

/************************ (C) COPYRIGHT STMicroelectronics *****END OF FILE****/
